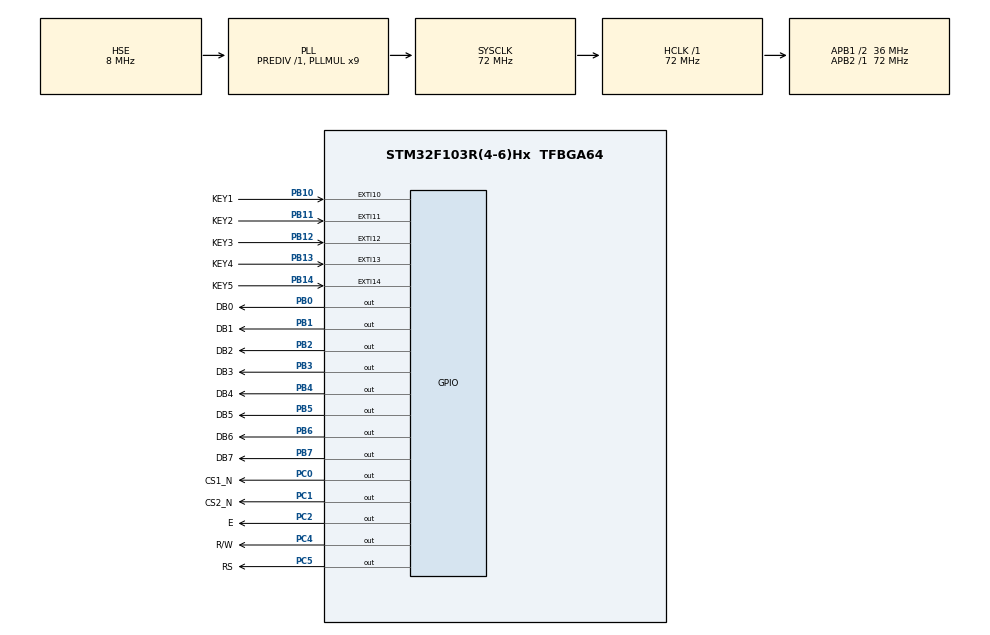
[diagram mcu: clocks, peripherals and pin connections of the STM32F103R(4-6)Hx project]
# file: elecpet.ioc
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Mcu.Family=STM32F1
Mcu.Name=STM32F103R(4-6)Hx
Mcu.Package=TFBGA64
NVIC.EXTI15_10_IRQn=true\:1\:0\:true\:true\:true\:1\:true\:true
NVIC.PriorityGroup=NVIC_PRIORITYGROUP_4
PB0.GPIO_Label=DB0
PB0.Signal=GPIO_Output
PB1.GPIO_Label=DB1
PB1.Signal=GPIO_Output
PB10.GPIO_Label=KEY1
PB10.GPIO_ModeDefaultEXTI=GPIO_MODE_IT_FALLING
PB10.GPIO_PuPd=GPIO_PULLUP
PB10.Signal=GPXTI10
PB11.GPIO_Label=KEY2
PB11.GPIO_ModeDefaultEXTI=GPIO_MODE_IT_FALLING
PB11.GPIO_PuPd=GPIO_PULLUP
PB11.Signal=GPXTI11
PB12.GPIO_Label=KEY3
PB12.GPIO_ModeDefaultEXTI=GPIO_MODE_IT_FALLING
PB12.GPIO_PuPd=GPIO_PULLUP
PB12.Signal=GPXTI12
PB13.GPIO_Label=KEY4
PB13.GPIO_ModeDefaultEXTI=GPIO_MODE_IT_FALLING
PB13.GPIO_PuPd=GPIO_PULLUP
PB13.Signal=GPXTI13
PB14.GPIO_Label=KEY5
PB14.GPIO_ModeDefaultEXTI=GPIO_MODE_IT_FALLING
PB14.GPIO_PuPd=GPIO_PULLUP
PB14.Signal=GPXTI14
PB2.GPIO_Label=DB2
PB2.Signal=GPIO_Output
PB3.GPIO_Label=DB3
PB3.Signal=GPIO_Output
PB4.GPIO_Label=DB4
PB4.Signal=GPIO_Output
PB5.GPIO_Label=DB5
PB5.Signal=GPIO_Output
PB6.GPIO_Label=DB6
PB6.Signal=GPIO_Output
PB7.GPIO_Label=DB7
PB7.Signal=GPIO_Output
PC0.GPIO_Label=CS1_N
PC0.Signal=GPIO_Output
PC1.GPIO_Label=CS2_N
PC1.Signal=GPIO_Output
PC2.GPIO_Label=E
PC2.Signal=GPIO_Output
PC4.GPIO_Label=R/W
PC4.Signal=GPIO_Output
PC5.GPIO_Label=RS
PC5.Signal=GPIO_Output
PD0-OSC_IN.Mode=HSE-External-Oscillator
PD0-OSC_IN.Signal=RCC_OSC_IN
PD1-OSC_OUT.Mode=HSE-External-Oscillator
PD1-OSC_OUT.Signal=RCC_OSC_OUT
ProjectManager.HeapSize=0x200
ProjectManager.StackSize=0x400
ProjectManager.TargetToolchain=MDK-ARM V5.27
RCC.AHBFreq_Value=72000000
RCC.APB1CLKDivider=RCC_HCLK_DIV2
RCC.APB1Freq_Value=36000000
RCC.APB1TimFreq_Value=72000000
RCC.APB2Freq_Value=72000000
RCC.APB2TimFreq_Value=72000000
RCC.EnbaleCSS=true
RCC.HCLKFreq_Value=72000000
RCC.PLLMUL=RCC_PLL_MUL9
RCC.PLLSourceVirtual=RCC_PLLSOURCE_HSE
RCC.SYSCLKFreq_VALUE=72000000
RCC.SYSCLKSource=RCC_SYSCLKSOURCE_PLLCLK
RCC.USBFreq_Value=72000000
VP_SYS_VS_ND.Mode=No_Debug
board=custom

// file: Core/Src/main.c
/* USER CODE BEGIN Header */
/**
  ******************************************************************************
  * @file           : main.c
  * @brief          : Main program body
  ******************************************************************************
  * @attention
  *
  * <h2><center>&copy; Copyright (c) 2020 STMicroelectronics.
  * All rights reserved.</center></h2>
  *
  * This software component is licensed by ST under BSD 3-Clause license,
  * the "License"; You may not use this file except in compliance with the
  * License. You may obtain a copy of the License at:
  *                        opensource.org/licenses/BSD-3-Clause
  *
  ******************************************************************************
  */
/* USER CODE END Header */
#include "main.h"

/* USER CODE BEGIN Includes */
#include "lcd12864.h"
#include "word_lib.h"
#include "key_exit.h"
/* USER CODE END Includes */

/* USER CODE BEGIN PV */
uchar page=0, line=0, colum=0;
u32 preMs=0;

extern uchar xiaoren[];
/* USER CODE END PV */

void SystemClock_Config(void);
static void MX_GPIO_Init(void);
static void MX_NVIC_Init(void);

int main(void)
{

  /* MCU Configuration--------------------------------------------------------*/

  /* Reset of all peripherals, Initializes the Flash interface and the Systick. */
  HAL_Init();

  /* USER CODE BEGIN Init */
	uchar initPage=0, initColum=0;
	uchar prePage=0, preColum=0, preLine=0;
  /* USER CODE END Init */

  /* Configure the system clock */
  SystemClock_Config();

  /* Initialize all configured peripherals */
  MX_GPIO_Init();

  /* Initialize interrupts */
  MX_NVIC_Init();
  /* USER CODE BEGIN 2 */
	prePage = initPage; preColum = initColum;
	LCDShowPicture(initPage,initColum,16,16,xiaoren);
  /* USER CODE END 2 */

  /* Infinite loop */
  while (1)
  {

    /* USER CODE BEGIN 3 */
		if(page!=prePage || colum!=preColum || line!=preLine){
			SelectStartLine(line);
			LCDShowPicture(page,colum,16,16,xiaoren);
		}
  }
  /* USER CODE END 3 */
}

void SystemClock_Config(void)
{
  RCC_OscInitTypeDef RCC_OscInitStruct = {0};
  RCC_ClkInitTypeDef RCC_ClkInitStruct = {0};

  /** Initializes the RCC Oscillators according to the specified parameters
  * in the RCC_OscInitTypeDef structure.
  */
  RCC_OscInitStruct.OscillatorType = RCC_OSCILLATORTYPE_HSE;
  RCC_OscInitStruct.HSEState = RCC_HSE_ON;
  RCC_OscInitStruct.HSEPredivValue = RCC_HSE_PREDIV_DIV1;
  RCC_OscInitStruct.HSIState = RCC_HSI_ON;
  RCC_OscInitStruct.PLL.PLLState = RCC_PLL_ON;
  RCC_OscInitStruct.PLL.PLLSource = RCC_PLLSOURCE_HSE;
  RCC_OscInitStruct.PLL.PLLMUL = RCC_PLL_MUL9;
  if (HAL_RCC_OscConfig(&RCC_OscInitStruct) != HAL_OK)
  {
    Error_Handler();
  }
  /** Initializes the CPU, AHB and APB buses clocks
  */
  RCC_ClkInitStruct.ClockType = RCC_CLOCKTYPE_HCLK|RCC_CLOCKTYPE_SYSCLK
                              |RCC_CLOCKTYPE_PCLK1|RCC_CLOCKTYPE_PCLK2;
  RCC_ClkInitStruct.SYSCLKSource = RCC_SYSCLKSOURCE_PLLCLK;
  RCC_ClkInitStruct.AHBCLKDivider = RCC_SYSCLK_DIV1;
  RCC_ClkInitStruct.APB1CLKDivider = RCC_HCLK_DIV2;
  RCC_ClkInitStruct.APB2CLKDivider = RCC_HCLK_DIV1;

  if (HAL_RCC_ClockConfig(&RCC_ClkInitStruct, FLASH_LATENCY_2) != HAL_OK)
  {
    Error_Handler();
  }
  /** Enables the Clock Security System
  */
  HAL_RCC_EnableCSS();
}

/**
  * @brief NVIC Configuration.
  * @retval None
  */
static void MX_NVIC_Init(void)
{
  /* EXTI15_10_IRQn interrupt configuration */
  HAL_NVIC_SetPriority(EXTI15_10_IRQn, 1, 0);
  HAL_NVIC_EnableIRQ(EXTI15_10_IRQn);
}

static void MX_GPIO_Init(void)
{
  GPIO_InitTypeDef GPIO_InitStruct = {0};

  /* GPIO Ports Clock Enable */
  __HAL_RCC_GPIOB_CLK_ENABLE();
  __HAL_RCC_GPIOD_CLK_ENABLE();
  __HAL_RCC_GPIOC_CLK_ENABLE();

  /*Configure GPIO pin Output Level */
  HAL_GPIO_WritePin(GPIOB, DB4_Pin|DB3_Pin|DB7_Pin|DB5_Pin
                          |DB6_Pin|DB0_Pin|DB1_Pin|DB2_Pin, GPIO_PIN_RESET);

  /*Configure GPIO pin Output Level */
  HAL_GPIO_WritePin(GPIOC, CS2_N_Pin|CS1_N_Pin|E_Pin|R_W_Pin
                          |RS_Pin, GPIO_PIN_RESET);

  /*Configure GPIO pins : DB4_Pin DB3_Pin DB7_Pin DB5_Pin
                           DB6_Pin DB0_Pin DB1_Pin DB2_Pin */
  GPIO_InitStruct.Pin = DB4_Pin|DB3_Pin|DB7_Pin|DB5_Pin
                          |DB6_Pin|DB0_Pin|DB1_Pin|DB2_Pin;
  GPIO_InitStruct.Mode = GPIO_MODE_OUTPUT_PP;
  GPIO_InitStruct.Pull = GPIO_NOPULL;
  GPIO_InitStruct.Speed = GPIO_SPEED_FREQ_LOW;
  HAL_GPIO_Init(GPIOB, &GPIO_InitStruct);

  /*Configure GPIO pins : CS2_N_Pin CS1_N_Pin E_Pin R_W_Pin
                           RS_Pin */
  GPIO_InitStruct.Pin = CS2_N_Pin|CS1_N_Pin|E_Pin|R_W_Pin
                          |RS_Pin;
  GPIO_InitStruct.Mode = GPIO_MODE_OUTPUT_PP;
  GPIO_InitStruct.Pull = GPIO_NOPULL;
  GPIO_InitStruct.Speed = GPIO_SPEED_FREQ_LOW;
  HAL_GPIO_Init(GPIOC, &GPIO_InitStruct);

  /*Configure GPIO pins : KEY5_Pin KEY1_Pin KEY4_Pin KEY2_Pin
                           KEY3_Pin */
  GPIO_InitStruct.Pin = KEY5_Pin|KEY1_Pin|KEY4_Pin|KEY2_Pin
                          |KEY3_Pin;
  GPIO_InitStruct.Mode = GPIO_MODE_IT_FALLING;
  GPIO_InitStruct.Pull = GPIO_PULLUP;
  HAL_GPIO_Init(GPIOB, &GPIO_InitStruct);

}

void Error_Handler(void)
{
  __disable_irq();
  while (1)
  {
  }
}

/************************ (C) COPYRIGHT STMicroelectronics *****END OF FILE****/
